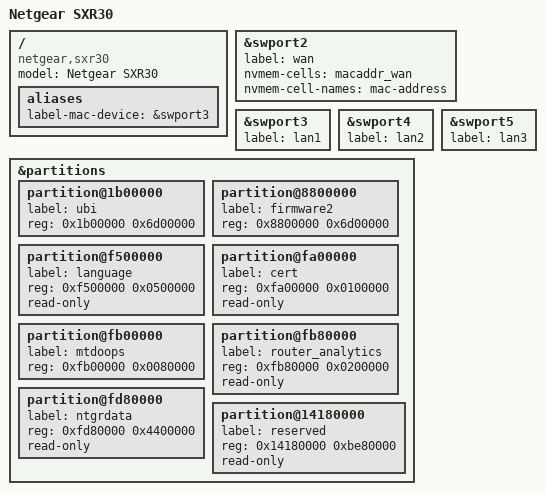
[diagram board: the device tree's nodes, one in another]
// SPDX-License-Identifier: GPL-2.0-or-later OR MIT

/dts-v1/;

#include "ipq6018-sxk30.dtsi"

/ {
	model = "Netgear SXR30";
	compatible = "netgear,sxr30", "qcom,ipq6018";

	aliases {
		label-mac-device = &swport3;
	};
};

&swport2 {
	label = "wan";
	nvmem-cells = <&macaddr_wan>;
	nvmem-cell-names = "mac-address";
};

&swport3 {
	label = "lan1";
};

&swport4 {
	label = "lan2";
};

&swport5 {
	label = "lan3";
};

&partitions {
	partition@1b00000 {
		label = "ubi";
		reg = <0x1b00000 0x6d00000>;
	};

	partition@8800000 {
		label = "firmware2";
		reg = <0x8800000 0x6d00000>;
	};

	partition@f500000 {
		label = "language";
		reg = <0xf500000 0x0500000>;
		read-only;
	};

	partition@fa00000 {
		label = "cert";
		reg = <0xfa00000 0x0100000>;
		read-only;
	};

	partition@fb00000 {
		label = "mtdoops";
		reg = <0xfb00000 0x0080000>;
	};

	partition@fb80000 {
		label = "router_analytics";
		reg = <0xfb80000 0x0200000>;
		read-only;
	};

	partition@fd80000 {
		label = "ntgrdata";
		reg = <0xfd80000 0x4400000>;
		read-only;
	};

	partition@14180000 {
		label = "reserved";
		reg = <0x14180000 0xbe80000>;
		read-only;
	};
};
